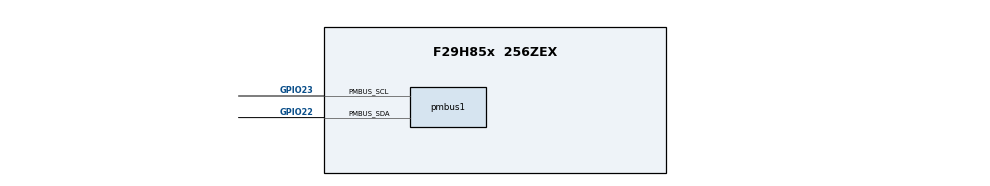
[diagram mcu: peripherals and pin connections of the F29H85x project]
/**
 * @cliArgs --device "F29H85x" --package "256ZEX" --part "F29H85x_256ZEX" --context "CPU1" --product "MCU_SDK_F29H85x@1.02.02.00"
 * @versions {"tool":"1.25.0+4237"}
 */

    
const divider15       = system.clockTree["PLL_REFDIV"];
divider15.divideValue = 1;

const multiplier1         = system.clockTree["PLL_IMULT"];
multiplier1.multiplyValue = 40;

const mux7       = system.clockTree["OSCCLKSRCSEL"];
mux7.inputSelect = "INTOSC2";

/**
 * Import the modules used in this configuration.
 */
const pmbus  = scripting.addModule("/driverlib/pmbus.js", {}, false);
const pmbus1 = pmbus.addInstance();
const jtag       = scripting.addModule("/driverlib/jtag.js");

/**
 * Write custom configuration values to the imported modules.
 */
pmbus1.$name                      = "myPMBUS0";
pmbus1.dataCount                  = 4;
pmbus1.useZeroHoldSupport         = true;
pmbus1.OwnAddress                 = 0x6A;
pmbus1.enableI2CMode              = true;
pmbus1.TargetAddress              = 0x5A;
pmbus1.useInterrupts              = true;
pmbus1.registerInterrupts         = true;
pmbus1.enabledInterrupts          = ["PMBUS_INT_DATA_REQUEST","PMBUS_INT_EOM"];
pmbus1.pmbus.$assign              = "PMBUSA";
pmbus1.pmbus.pmbus_sclPin.$assign = "GPIO23";
pmbus1.pmbus.pmbus_sdaPin.$assign = "GPIO22";
pmbus1.periphClock.$name          = "driverlib_perClock0";
pmbus1.periphConfig.$name         = "driverlib_perConfig0";
